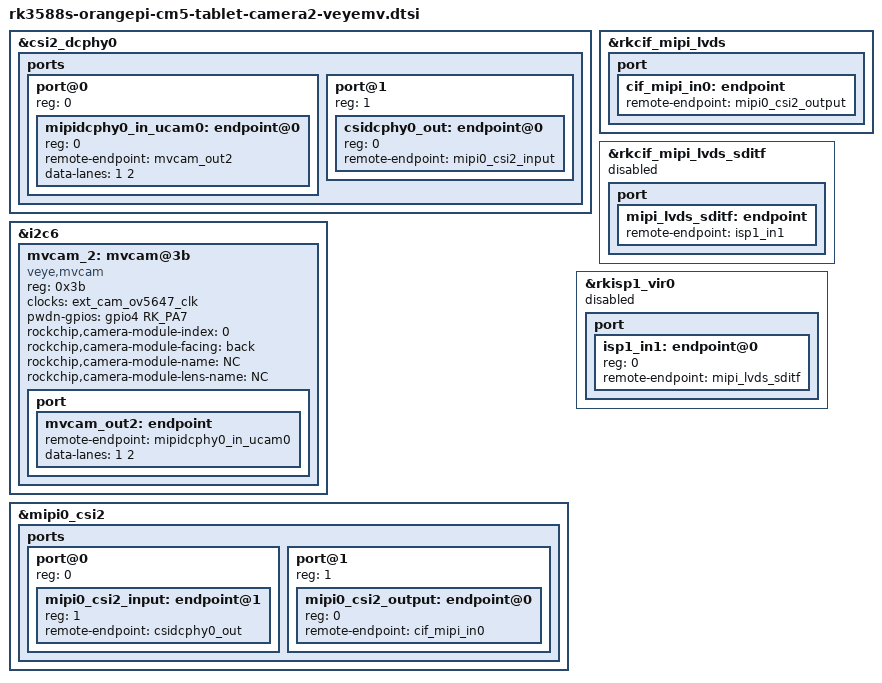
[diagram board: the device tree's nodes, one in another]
// SPDX-License-Identifier: (GPL-2.0+ OR MIT)
/*
 * Copyright (c) 2021 Rockchip Electronics Co., Ltd.
 *
 */

&csi2_dcphy0 {
	status = "okay";

	ports {
		#address-cells = <1>;
		#size-cells = <0>;
		port@0 {
			reg = <0>;
			#address-cells = <1>;
			#size-cells = <0>;

			mipidcphy0_in_ucam0: endpoint@0 {
				reg = <0>;
				remote-endpoint = <&mvcam_out2>;
				data-lanes = <1 2>;
			};
		};

		port@1 {
			reg = <1>;
			#address-cells = <1>;
			#size-cells = <0>;

			csidcphy0_out: endpoint@0 {
				reg = <0>;
				remote-endpoint = <&mipi0_csi2_input>;
			};
		};
	};
};

&i2c6 {
	status = "okay";


	mvcam_2: mvcam@3b{
		status = "okay";
        compatible = "veye,mvcam";
        reg = <0x3b>;
		clocks = <&ext_cam_ov5647_clk>;
		clock-names = "ext_cam_ov5647_clk";
		pwdn-gpios = <&gpio4 RK_PA7 GPIO_ACTIVE_HIGH>;
		rockchip,camera-module-index = <0>;
		rockchip,camera-module-facing = "back";
		rockchip,camera-module-name = "NC";
		rockchip,camera-module-lens-name = "NC";
		port {
			mvcam_out2: endpoint {
				remote-endpoint = <&mipidcphy0_in_ucam0>;
				data-lanes = <1 2>;
			};
		};
	};

};

&mipi0_csi2 {
	status = "okay";

	ports {
		#address-cells = <1>;
		#size-cells = <0>;

		port@0 {
			reg = <0>;
			#address-cells = <1>;
			#size-cells = <0>;

			mipi0_csi2_input: endpoint@1 {
				reg = <1>;
				remote-endpoint = <&csidcphy0_out>;
			};
		};

		port@1 {
			reg = <1>;
			#address-cells = <1>;
			#size-cells = <0>;

			mipi0_csi2_output: endpoint@0 {
				reg = <0>;
				remote-endpoint = <&cif_mipi_in0>;
			};
		};
	};
};

&rkcif_mipi_lvds {
	status = "okay";

	port {
		cif_mipi_in0: endpoint {
			remote-endpoint = <&mipi0_csi2_output>;
		};
	};
};

&rkcif_mipi_lvds_sditf {
	status = "disabled";

	port {
		mipi_lvds_sditf: endpoint {
			remote-endpoint = <&isp1_in1>;
		};
	};
};

&rkisp1_vir0 {
	status = "disabled";

	port {
		#address-cells = <1>;
		#size-cells = <0>;

		isp1_in1: endpoint@0 {
			reg = <0>;
			remote-endpoint = <&mipi_lvds_sditf>;
		};
	};
};
